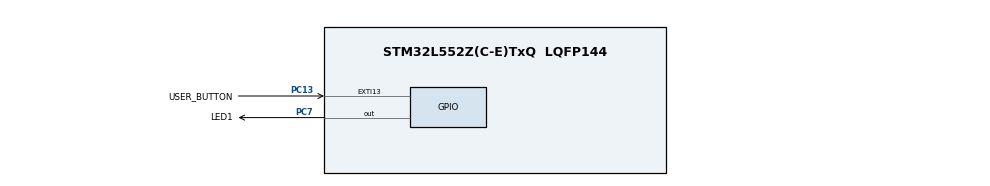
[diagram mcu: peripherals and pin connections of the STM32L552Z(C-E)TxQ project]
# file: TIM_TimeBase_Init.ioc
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Mcu.Family=STM32L5
Mcu.Name=STM32L552Z(C-E)TxQ
Mcu.Package=LQFP144
Mcu.TrustZone=disable
NVIC.EXTI13_IRQn=true\:0\:0\:false\:false\:true\:true\:true\:true
NVIC.PriorityGroup=NVIC_PRIORITYGROUP_3
NVIC.TIM1_BRK_IRQn=true\:0\:0\:false\:false\:true\:true\:true\:true
NVIC.TIM1_UP_IRQn=true\:0\:0\:false\:false\:true\:true\:true\:true
PC13.GPIO_Label=USER_BUTTON
PC13.GPIO_ModeDefaultEXTI=GPIO_MODE_IT_FALLING
PC13.GPIO_PuPd=GPIO_NOPULL
PC13.Signal=GPXTI13
PC7.GPIO_Label=LED1
PC7.Signal=GPIO_Output
ProjectManager.HeapSize=0x200
ProjectManager.StackSize=0x400
ProjectManager.TargetToolchain=EWARM V8.32
RCC.ADCCLockSelection=RCC_ADCCLKSOURCE_SYSCLK
RCC.ADCFreq_Value=110000000
RCC.AHBFreq_Value=110000000
RCC.APB1Freq_Value=110000000
RCC.APB1TimFreq_Value=110000000
RCC.APB2Freq_Value=110000000
RCC.APB2TimFreq_Value=110000000
RCC.CK48CLockSelection=RCC_USBCLKSOURCE_MSI
RCC.CortexFreq_Value=110000000
RCC.HCLKFreq_Value=110000000
RCC.HSE_VALUE=16000000
RCC.HSI48_VALUE=48000000
RCC.HSI_VALUE=16000000
RCC.I2C1CLockSelection=RCC_I2C1CLKSOURCE_SYSCLK
RCC.I2C3CLockSelection=RCC_I2C3CLKSOURCE_HSI
RCC.LSE_VALUE=32768
RCC.MSI_VALUE=4000000
RCC.PLLN=55
RCC.PLLSAI1N=24
RCC.SYSCLKFreq_VALUE=110000000
RCC.SYSCLKSource=RCC_SYSCLKSOURCE_PLLCLK
RCC.USBFreq_Value=4000000
RCC.VCOOutputFreq_Value=220000000
TIM1.AutoReloadPreload=TIM_AUTORELOAD_PRELOAD_DISABLE
TIM1.ClockDivision=TIM_CLOCKDIVISION_DIV1
TIM1.CounterMode=TIM_COUNTERMODE_UP
TIM1.Period=tim_period
TIM1.Prescaler=tim_prescaler
TIM1.RepetitionCounter=0
TIM1.TIM_MasterOutputTrigger=TIM_TRGO_RESET
TIM1.TIM_MasterOutputTrigger2=TIM_TRGO2_RESET
TIM1.TIM_MasterSlaveMode=TIM_MASTERSLAVEMODE_DISABLE
VP_ICACHE_VS_ICACHE.Mode=DirectMappedCache
VP_PWR_VS_DBSignals.Mode=DisableDeadBatterySignals
VP_TIM1_VS_ClockSourceINT.Mode=Internal
board=custom

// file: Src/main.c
/* USER CODE BEGIN Header */
/**
  ******************************************************************************
  * @file    Examples_LL/TIM/TIM_TimeBase_Init/Src/main.c
  * @author  MCD Application Team
  * @brief   This example describes how to use a timer instance to generate a
  *          time base using the STM32L5xx TIM LL API.
  *          Peripheral initialization done using LL unitary services functions.
  ******************************************************************************
  * @attention
  *
  * Copyright (c) 2019 STMicroelectronics.
  * All rights reserved.
  *
  * This software is licensed under terms that can be found in the LICENSE file
  * in the root directory of this software component.
  * If no LICENSE file comes with this software, it is provided AS-IS.
  *
  ******************************************************************************
  */
/* USER CODE END Header */
#include "main.h"

/* USER CODE BEGIN PD */
/* Number of time base frequencies */
#define TIM_BASE_FREQ_NB 10
/* USER CODE END PD */

/* USER CODE BEGIN PV */
static uint32_t tim_prescaler = 0;
static uint32_t tim_period = 0;
static uint32_t TimOutClock = 1;

/* Actual autoreload value multiplication factor */
static uint8_t AutoreloadMult = 1;
/* USER CODE END PV */

void SystemClock_Config(void);
static void MX_GPIO_Init(void);
static void MX_ICACHE_Init(void);
static void MX_TIM1_Init(void);

int main(void)
{

  /* MCU Configuration--------------------------------------------------------*/

  /* Reset of all peripherals, Initializes the Flash interface and the Systick. */
  LL_APB2_GRP1_EnableClock(LL_APB2_GRP1_PERIPH_SYSCFG);
  LL_APB1_GRP1_EnableClock(LL_APB1_GRP1_PERIPH_PWR);

  /* System interrupt init*/
  NVIC_SetPriorityGrouping(NVIC_PRIORITYGROUP_3);

  /** Disable the internal Pull-Up in Dead Battery pins of UCPD peripheral
  */
  LL_PWR_DisableUCPDDeadBattery();

  /* Configure the system clock */
  SystemClock_Config();

  /* USER CODE BEGIN SysInit */
  /* Set the pre-scaler value to have TIM1 counter clock equal to 10 kHz      */
  /*
In this example TIM1 input clock TIM1CLK is set to APB2 clock PCLK2 (TIM1CLK = PCLK2).
	As APB2 pre-scaler is equal to 1 PCLK2 = HCLK, and since AHB pre-scaler is equal to 1,
      => TIM1CLK = SystemCoreClock (110 MHz)
  */
  tim_prescaler = __LL_TIM_CALC_PSC(SystemCoreClock, 10000);

  /* TIM1CLK = SystemCoreClock / (APB prescaler & multiplier)              */
  TimOutClock = SystemCoreClock/1;
  tim_period = __LL_TIM_CALC_ARR(TimOutClock, tim_prescaler, 10);
  /* USER CODE END SysInit */

  /* Initialize all configured peripherals */
  MX_GPIO_Init();
  MX_ICACHE_Init();
  MX_TIM1_Init();
  /* USER CODE BEGIN 2 */
  /* Clear the update flag */
  LL_TIM_ClearFlag_UPDATE(TIM1);

  /* Enable the update interrupt */
  LL_TIM_EnableIT_UPDATE(TIM1);

  /* Enable counter */
  LL_TIM_EnableCounter(TIM1);
  /* USER CODE END 2 */

  /* Infinite loop */
  while (1)
  {

  }
}

void SystemClock_Config(void)
{
  LL_FLASH_SetLatency(LL_FLASH_LATENCY_5);
  while(LL_FLASH_GetLatency()!= LL_FLASH_LATENCY_5)
  {
  }

  LL_PWR_SetRegulVoltageScaling(LL_PWR_REGU_VOLTAGE_SCALE0);
  LL_RCC_MSI_Enable();

   /* Wait till MSI is ready */
  while(LL_RCC_MSI_IsReady() != 1)
  {
  }

  LL_RCC_MSI_EnableRangeSelection();
  LL_RCC_MSI_SetRange(LL_RCC_MSIRANGE_6);
  LL_RCC_MSI_SetCalibTrimming(0);
  LL_RCC_PLL_ConfigDomain_SYS(LL_RCC_PLLSOURCE_MSI, LL_RCC_PLLM_DIV_1, 55, LL_RCC_PLLR_DIV_2);
  LL_RCC_PLL_EnableDomain_SYS();
  LL_RCC_PLL_Enable();

   /* Wait till PLL is ready */
  while(LL_RCC_PLL_IsReady() != 1)
  {
  }

   /* Intermediate AHB prescaler 2 when target frequency clock is higher than 80 MHz */
   LL_RCC_SetAHBPrescaler(LL_RCC_SYSCLK_DIV_2);

  LL_RCC_SetSysClkSource(LL_RCC_SYS_CLKSOURCE_PLL);

   /* Wait till System clock is ready */
  while(LL_RCC_GetSysClkSource() != LL_RCC_SYS_CLKSOURCE_STATUS_PLL)
  {
  }

  /* Insure 1us transition state at intermediate medium speed clock*/
  for (__IO uint32_t i = (RCC_MAX_FREQUENCY_MHZ >> 1); i !=0; i--);

  LL_RCC_SetAHBPrescaler(LL_RCC_SYSCLK_DIV_1);
  LL_RCC_SetAPB1Prescaler(LL_RCC_APB1_DIV_1);
  LL_RCC_SetAPB2Prescaler(LL_RCC_APB2_DIV_1);

  LL_Init1msTick(110000000);

  LL_SetSystemCoreClock(110000000);
}

static void MX_ICACHE_Init(void)
{

  /** Enable instruction cache in 1-way (direct mapped cache)
  */
  LL_ICACHE_SetMode(LL_ICACHE_1WAY);
  LL_ICACHE_Enable();

}

static void MX_TIM1_Init(void)
{

  LL_TIM_InitTypeDef TIM_InitStruct = {0};

  /* Peripheral clock enable */
  LL_APB2_GRP1_EnableClock(LL_APB2_GRP1_PERIPH_TIM1);

  /* TIM1 interrupt Init */
  NVIC_SetPriority(TIM1_BRK_IRQn, NVIC_EncodePriority(NVIC_GetPriorityGrouping(),0, 0));
  NVIC_EnableIRQ(TIM1_BRK_IRQn);
  NVIC_SetPriority(TIM1_UP_IRQn, NVIC_EncodePriority(NVIC_GetPriorityGrouping(),0, 0));
  NVIC_EnableIRQ(TIM1_UP_IRQn);

  TIM_InitStruct.Prescaler = tim_prescaler;
  TIM_InitStruct.CounterMode = LL_TIM_COUNTERMODE_UP;
  TIM_InitStruct.Autoreload = tim_period;
  TIM_InitStruct.ClockDivision = LL_TIM_CLOCKDIVISION_DIV1;
  TIM_InitStruct.RepetitionCounter = 0;
  LL_TIM_Init(TIM1, &TIM_InitStruct);
  LL_TIM_DisableARRPreload(TIM1);
  LL_TIM_SetClockSource(TIM1, LL_TIM_CLOCKSOURCE_INTERNAL);
  LL_TIM_SetTriggerOutput(TIM1, LL_TIM_TRGO_RESET);
  LL_TIM_SetTriggerOutput2(TIM1, LL_TIM_TRGO2_RESET);
  LL_TIM_DisableMasterSlaveMode(TIM1);

}

static void MX_GPIO_Init(void)
{
  LL_EXTI_InitTypeDef EXTI_InitStruct = {0};
  LL_GPIO_InitTypeDef GPIO_InitStruct = {0};

  /* GPIO Ports Clock Enable */
  LL_AHB2_GRP1_EnableClock(LL_AHB2_GRP1_PERIPH_GPIOC);

  /**/
  LL_GPIO_ResetOutputPin(LED1_GPIO_Port, LED1_Pin);

  /**/
  LL_EXTI_SetEXTISource(LL_EXTI_EXTI_PORTC, LL_EXTI_EXTI_LINE13);

  /**/
  EXTI_InitStruct.Line_0_31 = LL_EXTI_LINE_13;
  EXTI_InitStruct.Line_32_63 = LL_EXTI_LINE_NONE;
  EXTI_InitStruct.LineCommand = ENABLE;
  EXTI_InitStruct.Mode = LL_EXTI_MODE_IT;
  EXTI_InitStruct.Trigger = LL_EXTI_TRIGGER_FALLING;
  LL_EXTI_Init(&EXTI_InitStruct);

  /**/
  LL_GPIO_SetPinPull(USER_BUTTON_GPIO_Port, USER_BUTTON_Pin, LL_GPIO_PULL_NO);

  /**/
  LL_GPIO_SetPinMode(USER_BUTTON_GPIO_Port, USER_BUTTON_Pin, LL_GPIO_MODE_INPUT);

  /**/
  GPIO_InitStruct.Pin = LED1_Pin;
  GPIO_InitStruct.Mode = LL_GPIO_MODE_OUTPUT;
  GPIO_InitStruct.Speed = LL_GPIO_SPEED_FREQ_LOW;
  GPIO_InitStruct.OutputType = LL_GPIO_OUTPUT_PUSHPULL;
  GPIO_InitStruct.Pull = LL_GPIO_PULL_NO;
  LL_GPIO_Init(LED1_GPIO_Port, &GPIO_InitStruct);

  /* EXTI interrupt init*/
  NVIC_SetPriority(EXTI13_IRQn, NVIC_EncodePriority(NVIC_GetPriorityGrouping(),0, 0));
  NVIC_EnableIRQ(EXTI13_IRQn);

}

/* USER CODE BEGIN 4 */

/******************************************************************************/
/*   USER IRQ HANDLER TREATMENT                                               */
/******************************************************************************/
/**
  * @brief  Update the timer update event period
  * @param  None
  * @retval None
  */
void UserButton_Callback(void)
{
  /* Change the update event period by modifying the autoreload value.        */
  /* In up-counting update event is generated at each counter overflow (when  */
  /* the counter reaches the auto-reload value).                              */
  /* Update event period is calculated as follows:                            */
  /*   Update_event = TIM1CLK /((PSC + 1)*(ARR + 1)*(RCR + 1))                */
  /*   where TIM1CLK is 110 MHz                                                */
  AutoreloadMult = AutoreloadMult % TIM_BASE_FREQ_NB;
  LL_TIM_SetAutoReload(TIM1, tim_period * (AutoreloadMult +1));

  /* Force update generation */
  LL_TIM_GenerateEvent_UPDATE(TIM1);

  AutoreloadMult++;
}

/**
  * @brief  Timer update interrupt processing
  * @param  None
  * @retval None
  */
void TimerUpdate_Callback(void)
{
  LL_GPIO_TogglePin(LED1_GPIO_Port, LED1_Pin);
}
/* USER CODE END 4 */

void Error_Handler(void)
{
  while(1)
  {
  }
}
